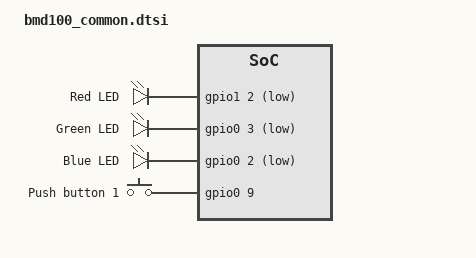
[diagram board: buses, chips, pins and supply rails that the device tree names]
/ {

    leds {
        compatible = "gpio-leds";
        led0: led_0 {
            gpios = <&gpio1 2 GPIO_ACTIVE_LOW>;
            label = "Red LED";
        };
        led1: led_1 {
            gpios = <&gpio0 3 GPIO_ACTIVE_LOW>;
            label = "Green LED";
        };
        led2: led_2 {
            gpios = <&gpio0 2 GPIO_ACTIVE_LOW>;
            label = "Blue LED";
        };
    };

    buttons {
        compatible = "gpio-keys";
        button0: button_0 {
            gpios = <&gpio0 9 (GPIO_ACTIVE_HIGH)>;
            label = "Push button 1";
            zephyr,code = <INPUT_KEY_0>;
        };
    };

    /* These aliases are provided for compatibility with samples */
	aliases {
		led0 = &led0;
		led1 = &led1;
		led2 = &led2;
		sw0 = &button0;
		bootloader-led0 = &led0;
		mcuboot-button0 = &button0;
		mcuboot-led0 = &led0;
	};
};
